# GD32H7xx register map
File version: 1.0
CPU: CM7 r1p2, little endian, MPU, FPU, 4 interrupt priority bits
Registers are 32-bit, read-write, reset 0x0 unless marked. A register's access mark holds for its fields unless they carry their own. Offsets are from the block's base; [hi:lo] are bit positions; {n}, {i} and the like mark numbered series.

## EXTI — External interrupt/event controller
Base 0x58000000
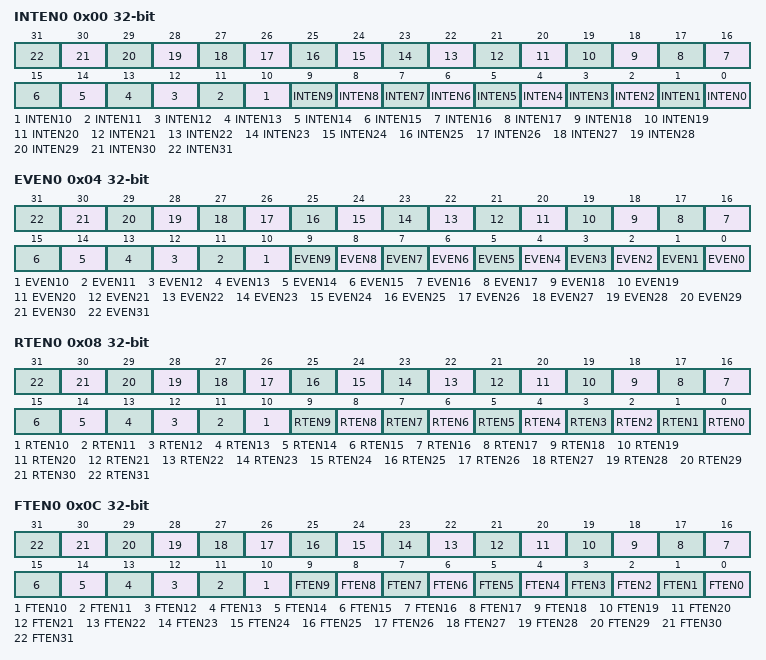
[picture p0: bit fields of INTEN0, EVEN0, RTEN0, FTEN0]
0x00 INTEN0 — Interrupt enable register 0 (EXTI_INTEN0)
  [n] INTEN{n} (n=0..31) — Enable Interrupt on line {n}
0x04 EVEN0 — Event enable register 0 (EXTI_EVEN0)
  [n] EVEN{n} (n=0..31) — Enable Event on line {n}
0x08 RTEN0 — Rising Edge Trigger Enable register 0 (EXTI_RTEN0)
  [n] RTEN{n} (n=0..31) — Rising edge trigger enable of line {n}
0x0C FTEN0 — Falling Egde Trigger Enable register 0 (EXTI_FTEN0)
  [n] FTEN{n} (n=0..31) — Falling edge trigger enable of line {n}
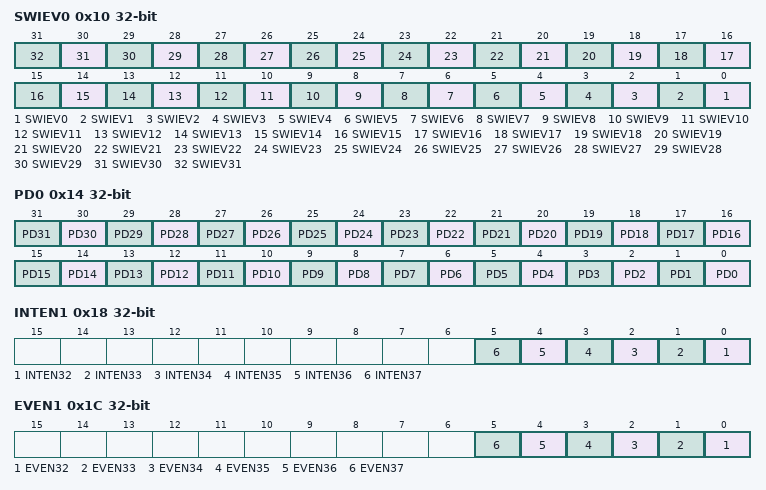
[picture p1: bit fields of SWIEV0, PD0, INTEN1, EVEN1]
0x10 SWIEV0 — Software interrupt event register (EXTI_SWIEV0)
  [n] SWIEV{n} (n=0..31) — Interrupt/Event software trigger on line {n}
0x14 PD0 — Pending register (EXTI_PD0)
  [n] PD{n} (n=0..31) — Interrupt pending status of line {n}
0x18 INTEN1 — Interrupt enable register 0 (EXTI_INTEN1)
  [n-32] INTEN{n} (n=32..37) — Enable Interrupt on line {n}
0x1C EVEN1 — Event enable register 1 (EXTI_EVEN1)
  [n-32] EVEN{n} (n=32..37) — Enable Event on line {n}
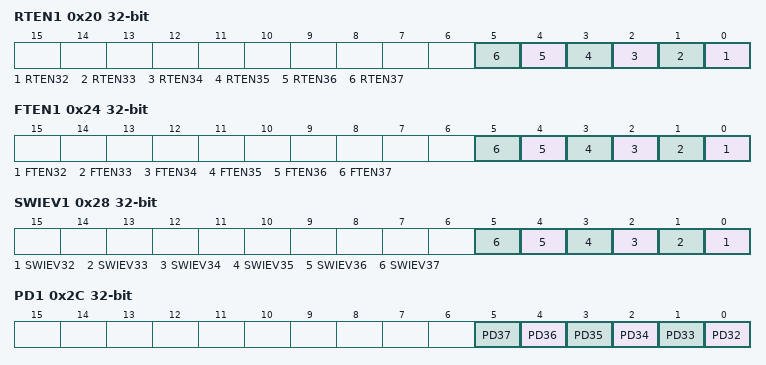
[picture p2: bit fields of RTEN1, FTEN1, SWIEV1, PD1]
0x20 RTEN1 — Rising Edge Trigger Enable register 1 (EXTI_RTEN1)
  [n-32] RTEN{n} (n=32..37) — Rising edge trigger enable of line {n}
0x24 FTEN1 — Falling Egde Trigger Enable register 1 (EXTI_FTEN1)
  [n-32] FTEN{n} (n=32..37) — Falling edge trigger enable of line {n}
0x28 SWIEV1 — Software interrupt event register (EXTI_SWIEV1)
  [n-32] SWIEV{n} (n=32..37) — Interrupt/Event software trigger on line {n}
0x2C PD1 — Pending register (EXTI_PD1)
  [n-32] PD{n} (n=32..37) — Interrupt pending status of line {n}

## ENET0_MAC_FCTH — MAC flow control threshold register
Base 0x40029080
Same registers: ENET1_MAC_FCTH 0x4002B080
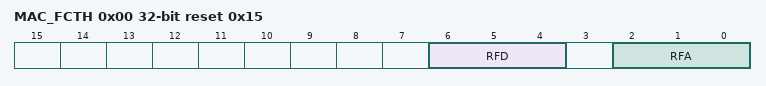
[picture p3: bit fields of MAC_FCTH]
0x00 MAC_FCTH reset 0x15 — Ethernet MAC flow control threshold register
  [6:4] RFD — Threshold of deactive flow control
  [2:0] RFA — Threshold of active flow control

## ENET0_MSC — Ethernet: MAC statistics counters
Base 0x40028100
Same registers: ENET1_MSC 0x4002A100
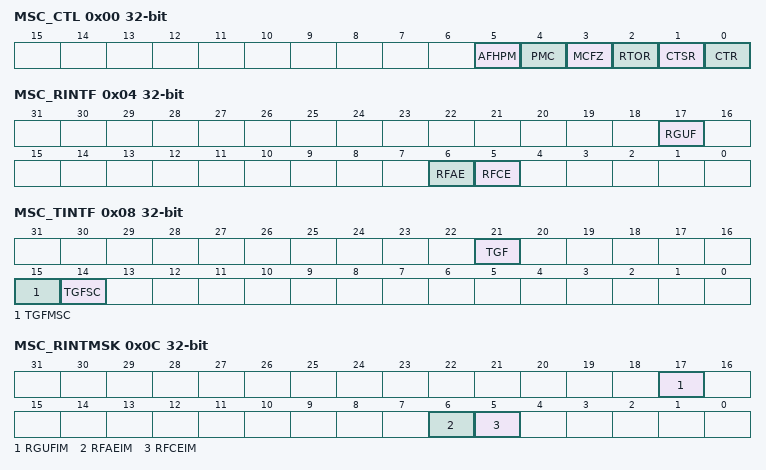
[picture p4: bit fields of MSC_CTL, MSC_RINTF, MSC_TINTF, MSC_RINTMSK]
0x00 MSC_CTL — Ethernet MSC control register (MSC_CTL)
  [5] AFHPM — Almost full or half preset mode
  [4] PMC wo — Preset MSC counter
  [3] MCFZ — MSC counter freeze
  [2] RTOR — Reset on read
  [1] CTSR — Counter stop rollover
  [0] CTR — Counter reset
0x04 MSC_RINTF ro — Ethernet MSC receive interrupt flag register (MSC_RINTF)
  [17] RGUF — Received Good Unicast Frames
  [6] RFAE — Received frames alignment error
  [5] RFCE — Received frames CRC error
0x08 MSC_TINTF ro — Ethernet MSC transmit interrupt flag register (MSC_TINTF)
  [21] TGF — Transmitted good frames
  [15] TGFMSC — Transmitted good frames more single collision
  [14] TGFSC — Transmitted good frames single collision
0x0C MSC_RINTMSK — Ethernet MSC receive interrupt mask register (MSC_RINTMSK)
  [17] RGUFIM — Received good unicast frames interrupt mask
  [6] RFAEIM — Received frames alignment error interrupt mask
  [5] RFCEIM — Received frame CRC error interrupt mask
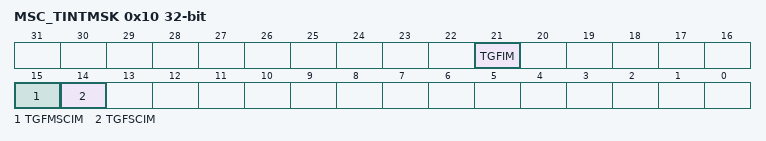
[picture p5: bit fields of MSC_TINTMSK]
0x10 MSC_TINTMSK — Ethernet MSC transmit interrupt mask register (MSC_TINTMSK)
  [21] TGFIM — Transmitted good frames interrupt mask
  [15] TGFMSCIM — Transmitted good frames more single interrupt collision mask
  [14] TGFSCIM — Transmitted good frames single collision interrupt mask
0x4C MSC_SCCNT ro — Ethernet MSC transmitted good frames after a single collision counter
  [31:0] SCC — Transmitted good frames after a single collision counter
0x50 MSC_MSCCNT ro — Ethernet MSC transmitted good frames after more than a single collision
  [31:0] MSCC — Transmitted good frames after more than a single collision counter
0x68 MSC_TGFCNT ro — Ethernet MSC transmitted good frames counter register
  [31:0] TGF — Transmitted good frames counter
0x94 MSC_RFCECNT ro — Ethernet MSC received frames with CRC error counter register
  [31:0] RFCER — Received frames with CRC error counter
0x98 MSC_RFAECNT ro — Ethernet MSC received frames with alignment error counter register
  [31:0] RFAER — Received frames with alignment error counter
0xC4 MSC_RGUFCNT ro — MSC received good unicast frames counter register
  [31:0] RGUF — Received good unicast frames counter
